# G32R430xx register map
Vendor: Geehy Semiconductor Co., Ltd.; Series: G32R4; File version: 1.0
CPU: CM52 r0p1, little endian, MPU, no FPU, DSP, VTOR, 4 interrupt priority bits
Registers are 32-bit, read-write, reset 0x0 unless marked. A register's access mark holds for its fields unless they carry their own. Offsets are from the block's base; [hi:lo] are bit positions; {n}, {i} and the like mark numbered series.

## WWDT — Window watchdog
Base 0x40002000
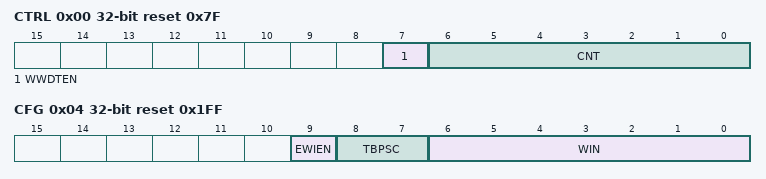
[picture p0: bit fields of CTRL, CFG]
0x00 CTRL reset 0x7F — Control register
  [7] WWDTEN — Activation bit
  [6:0] CNT — 7-bit counter (MSB to LSB)
0x04 CFG reset 0x1FF — Configuration register
  [9] EWIEN — Early wakeup interrupt
  [8:7] TBPSC — Timer Base Prescaler Factor Configure
  [6:0] WIN — 7-bit window value
0x08 STS — Status register
  [0] EWIFLG — Early wakeup interrupt flag

## IWDT — Independent watchdog
Base 0x40002400
0x00 KEY wo
  [15:0] KEY — Key value (write only, read 0000h)
0x04 PSC reset 0x7 — Prescaler register
  [2:0] PSC — Prescaler divider
0x08 CNTRLD reset 0xFFF — Reload register
  [11:0] CNTRLD — Watchdog counter reload value
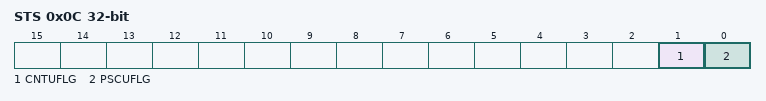
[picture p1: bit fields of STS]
0x0C STS ro — Status register
  [1] CNTUFLG — Watchdog counter reload value update
  [0] PSCUFLG — Watchdog prescaler value update

## EINT — External Interrupt
Base 0x40002800
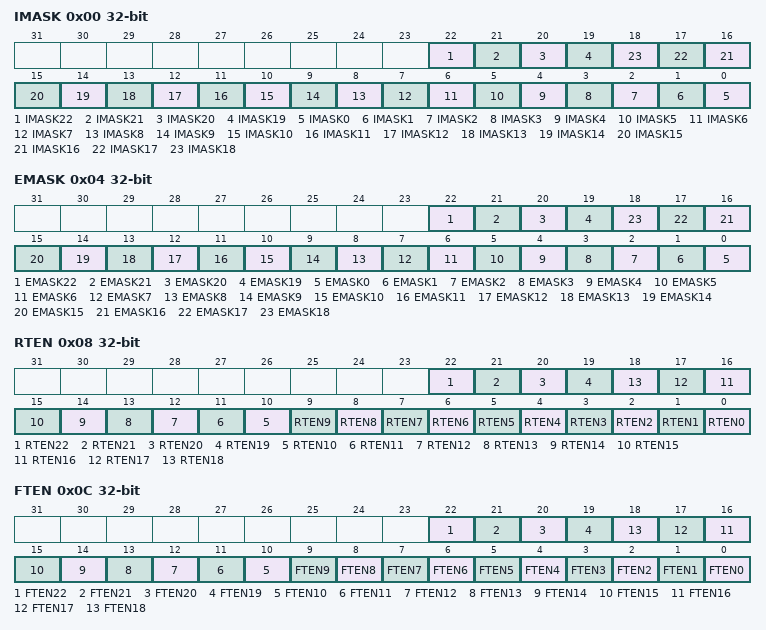
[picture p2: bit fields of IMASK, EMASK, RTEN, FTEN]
0x00 IMASK — Interrupt mask register
  [22] IMASK22 — Interrupt Mask on line 22
  [21] IMASK21 — Interrupt Mask on line 21
  [20] IMASK20 — Interrupt Mask on line 18
  [19] IMASK19 — Interrupt Mask on line 18
  [n] IMASK{n} (n=0..18) — Interrupt Mask on line {n}
0x04 EMASK — Event mask register
  [22] EMASK22 — Event Mask on line 22
  [21] EMASK21 — Event Mask on line 21
  [20] EMASK20 — Event Mask on line 18
  [19] EMASK19 — Event Mask on line 18
  [n] EMASK{n} (n=0..18) — Event Mask on line {n}
0x08 RTEN — Rising Trigger selection register
  [22] RTEN22 — Rising trigger event configuration of line 22
  [21] RTEN21 — Rising trigger event configuration of line 21
  [20] RTEN20 — Rising trigger event configuration of line 18
  [19] RTEN19 — Rising trigger event configuration of line 18
  [n] RTEN{n} (n=0..18) — Rising trigger event configuration of line {n}
0x0C FTEN — Falling Trigger selection register
  [22] FTEN22 — Falling trigger event configuration of line 22
  [21] FTEN21 — Falling trigger event configuration of line 21
  [20] FTEN20 — Falling trigger event configuration of line 18
  [19] FTEN19 — Falling trigger event configuration of line 18
  [n] FTEN{n} (n=0..18) — Falling trigger event configuration of line {n}
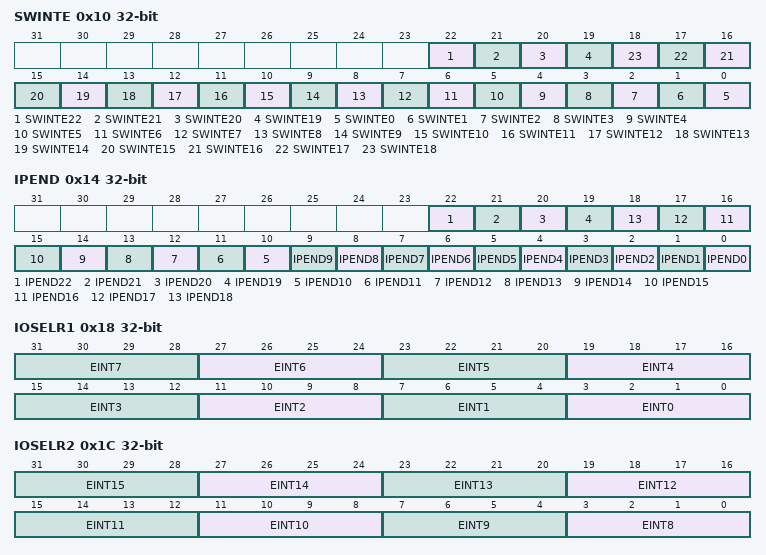
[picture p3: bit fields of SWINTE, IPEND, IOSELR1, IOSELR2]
0x10 SWINTE — Software interrupt event register
  [22] SWINTE22 — Software Interrupt on line 22
  [21] SWINTE21 — Software Interrupt on line 21
  [20] SWINTE20 — Software Interrupt on line 18
  [19] SWINTE19 — Software Interrupt on line 18
  [n] SWINTE{n} (n=0..18) — Software Interrupt on line {n}
0x14 IPEND — Pending register
  [22] IPEND22 — Pending bit 22
  [21] IPEND21 — Pending bit 21
  [20] IPEND20 — Pending bit 18
  [19] IPEND19 — Pending bit 18
  [n] IPEND{n} (n=0..18) — Pending bit {n}
0x18 IOSELR1 — Configure Register 1.
  [4n+3:4n] EINT{n} (n=0..7) — EXTI{n}
0x1C IOSELR2 — Configure Register 2.
  [4n-29:4n-32] EINT{n} (n=8..15) — EXTI{n}

## DAC1 — Digital to analog converter
Base 0x40002C00
Same registers: DAC2 0x40003000
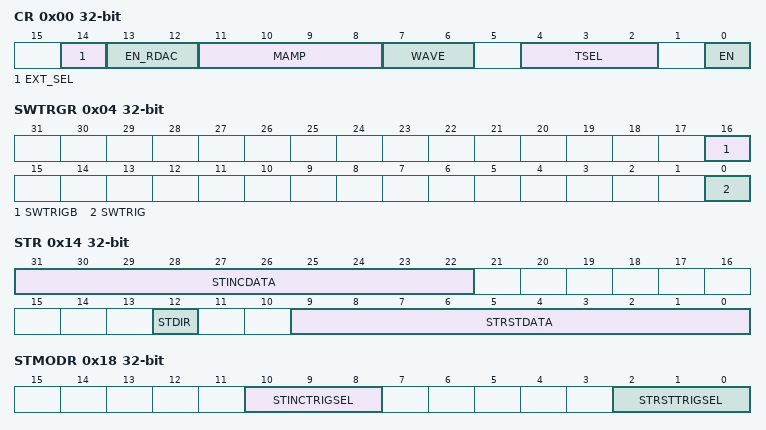
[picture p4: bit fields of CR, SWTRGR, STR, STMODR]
0x00 CR — Control register (DAC_CTRL)
  [14] EXT_SEL — BUFFER output connected to the PAD
  [13:12] EN_RDAC — Switch to control the DAC resistor ladder output signal to the op-amp input.
  [11:8] MAMP — DAC channel mute/amplitude selector
  [7:6] WAVE — DAC channel noise/triangle wave generation enable
  [4:2] TSEL — DAC channel trigger selection
  [0] EN — DAC channel1 enable
0x04 SWTRGR wo — DAC software trigger register(DAC_SWTRG)
  [16] SWTRIGB — DAC channel software b trigger
  [0] SWTRIG — DAC channel software trigger
0x08 DHR10R — DAC channel1 10-bit right-aligned data holding register(DAC_DH12R1)
  [9:0] DHR10R — DAC channel1 10-bit right-aligned data
0x0C DHR10L — DAC channel1 10-bit left aligned data holding register (DAC_DH12L1)
  [15:6] DHR10L — DAC channel1 10-bit left-aligned data
0x10 DOR ro — DAC channel data output register
  [9:0] DOR — DAC channel data output
0x14 STR — DAC channel sawtooth wave register.
  [31:22] STINCDATA — DAC channel sawtooth wave increment value
  [12] STDIR — DAC channel sawtooth wave direction setting
  [9:0] STRSTDATA — DAC channel sawtooth wave reset value
0x18 STMODR — DAC channel sawtooth wave trigger register
  [10:8] STINCTRIGSEL — DAC Channel Sawtooth Wave Incremental Trigger Selection
  [2:0] STRSTTRIGSEL — DAC channel sawtooth wave reset trigger selection.
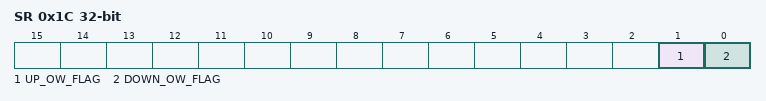
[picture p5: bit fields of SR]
0x1C SR — DAC status register
  [1] UP_OW_FLAG — DOR Data Upflow Flag
  [0] DOWN_OW_FLAG — DOR Data Underflow Flag
